# STM32N657 register map
File version: 1.0
CPU: CM55 r0p1, little endian, no MPU, FPU, vendor SysTick, 8 interrupt priority bits
Registers are 32-bit, read-write, reset 0x0 unless marked. A register's access mark holds for its fields unless they carry their own. Offsets are from the block's base; [hi:lo] are bit positions; {n}, {i} and the like mark numbered series.

## IWDG — Independent watchdog
Base 0x46004800
Same registers: IWDG_S 0x56004800
0x00 IWDG_KR wo — IWDG key register
  [15:0] KEY — Key value (write only, read 0x0000)
0x04 IWDG_PR — IWDG prescaler register
  [3:0] PR — Prescaler divider
    0=divider / 4; 1=divider / 8; 2=divider / 16; 3=divider / 32; 4=divider / 64; 5=divider / 128; 6=divider / 256; 7=divider / 512
0x08 IWDG_RLR reset 0xFFF — IWDG reload register
  [11:0] RL — Watchdog counter reload value
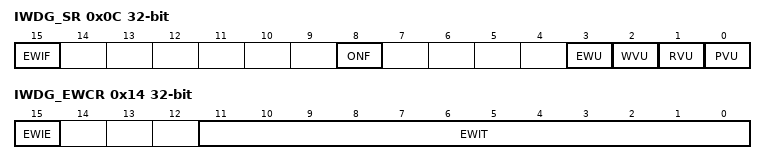
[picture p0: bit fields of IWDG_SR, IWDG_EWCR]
0x0C IWDG_SR ro — IWDG status register
  [15] EWIF — Watchdog early interrupt flag
  [8] ONF — Watchdog enable status bit
    0=The IWDG is not activated; 1=The IWDG is activated and needs to be refreshed regularly by the application
  [3] EWU — Watchdog interrupt comparator value update
  [2] WVU — Watchdog counter window value update
  [1] RVU — Watchdog counter reload value update
  [0] PVU — Watchdog prescaler value update
0x10 IWDG_WINR reset 0xFFF — IWDG window register
  [11:0] WIN — Watchdog counter window value
0x14 IWDG_EWCR — IWDG early wake-up interrupt register
  [15] EWIE — Watchdog early interrupt enable
    0=The early interrupt interface is disabled; 1=The early interrupt interface is enabled
  [11:0] EWIT — Watchdog counter window value
0x18 IWDG_ICR — IWDG interrupt clear register
  [15] EWIC — Watchdog early interrupt acknowledge

## MDIOS — Management data input/output
Base 0x40009400
Same registers: MDIOS_S 0x50009400
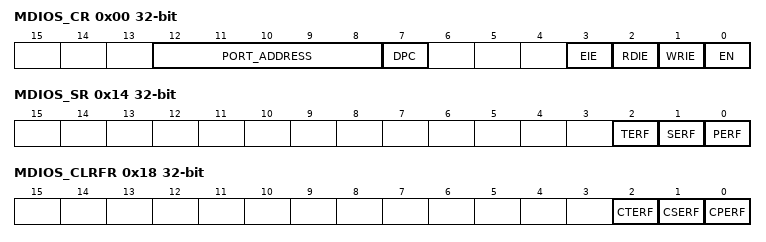
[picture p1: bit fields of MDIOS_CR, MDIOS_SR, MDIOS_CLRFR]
0x00 MDIOS_CR — MDIOS configuration register
  [12:8] PORT_ADDRESS — slave address
  [7] DPC — disable preamble check
    0=MDIO master must give preamble before each frame; 1=MDIO master can send each frame without a preceding preamble, and the MDIOS does not signal a preamble error
  [3] EIE — error interrupt enable
    0=Interrupt is disabled; 1=Interrupt is enabled
  [2] RDIE — register read interrupt enable
    0=Interrupt is disabled; 1=Interrupt is enabled
  [1] WRIE — register write interrupt enable
    0=Interrupt is disabled; 1=Interrupt is enabled
  [0] EN — peripheral enable
    0=MDIOS is disabled; 1=MDIOS is enabled and monitoring the MDIO bus (MDC/MDIO)
0x04 MDIOS_WRFR ro — MDIOS write flag register
  [31:0] WRF — write flags for MDIOS registers 0 to 31.
    0=MDIOS register x is not written by the MDIO master; 1=MDIOS register x is written by the MDIO master and the data is available in DIN[15:0] in the MDIOS_DINRx register
0x08 MDIOS_CWRFR — MDIOS clear write flag register
  [31:0] CWRF — clear the write flag
0x0C MDIOS_RDFR ro — MDIOS read flag register
  [31:0] RDF — read flags for MDIOS registers 0 to 31.
    0=MDIOS register x is not read by the MDIO master; 1=MDIOS register x is read by the MDIO master
0x10 MDIOS_CRDFR — MDIOS clear read flag register
  [31:0] CRDF — clear the read flag
0x14 MDIOS_SR ro — MDIOS status register
  [2] TERF — turnaround error flag
    0=No turnaround error has occurred; 1=A turnaround error has occurred
  [1] SERF — start error flag
    0=No start error has occurred; 1=A start error has occurred
  [0] PERF — preamble error flag
    0=No preamble error has occurred; 1=A preamble error has occurred
0x18 MDIOS_CLRFR — MDIOS clear flag register
  [2] CTERF — clear the turnaround error flag
  [1] CSERF — clear the start error flag
  [0] CPERF — clear the preamble error flag
{0x100+4i} MDIOS_DINR{i} ro (i=0..31) — MDIOS input data register {i}
  [15:0] DIN — input data received from MDIO master during write frames
{0x180+4i} MDIOS_DOUTR{i} (i=0..31) — MDIOS output data register {i}
  [15:0] DOUT — output data sent to MDIO Master during read frames

## PKA — Public key accelerator
Base 0x44022000
Same registers: PKA_S 0x54022000
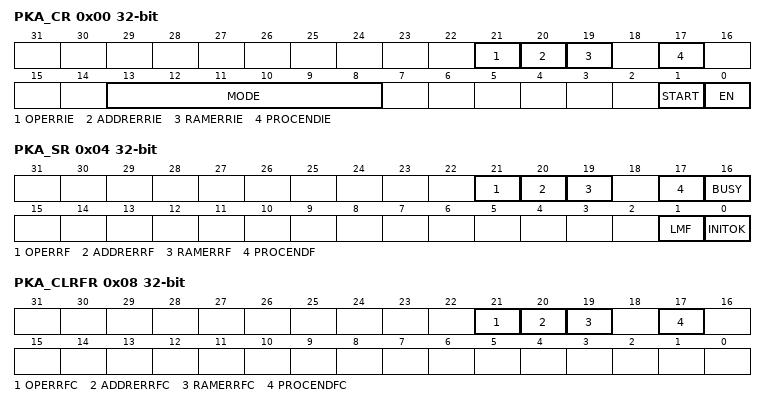
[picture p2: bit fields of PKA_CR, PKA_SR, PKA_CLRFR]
0x00 PKA_CR — PKA control register
  [21] OPERRIE — Operation error interrupt enable
    0=No interrupt is generated when OPERRF flag is set in PKA_SR; 1=An interrupt is generated when OPERRF flag is set in PKA_SR
  [20] ADDRERRIE — Address error interrupt enable
    0=No interrupt is generated when ADDRERRF flag is set in PKA_SR; 1=An interrupt is generated when ADDRERRF flag is set in PKA_SR
  [19] RAMERRIE — RAM error interrupt enable
    0=No interrupt is generated when RAMERRF flag is set in PKA_SR; 1=An interrupt is generated when RAMERRF flag is set in PKA_SR
  [17] PROCENDIE — End of operation interrupt enable
    0=No interrupt is generated when PROCENDF flag is set in PKA_SR; 1=An interrupt is generated when PROCENDF flag is set in PKA_SR
  [13:8] MODE — PKA operation code
    0=Montgomery parameter computation then modular exponentiation; 1=Montgomery parameter computation only; 2=Modular exponentiation only (Montgomery parameter must be loaded first); 3=Modular exponentiation (protected, used when manipulating secrets); 32=Montgomery parameter computation then ECC scalar multiplication; 36=ECDSA sign; 38=ECDSA verification; 40=Point on elliptic curve Fp check; 7=RSA CRT exponentiation; 8=Modular inversion; 9=Arithmetic addition; 10=Arithmetic subtraction; 11=Arithmetic multiplication; 12=Arithmetic comparison; 13=Modular reduction; 14=Modular addition; 15=Modular subtraction; 16=Montgomery multiplication; 35=ECC complete addition; 39=ECC double base ladder; 47=ECC projective to affine
  [1] START — start the operation
  [0] EN — PKA enable.
    0=Disable PKA; 1=Enable PKA.PKA becomes functional when INITOK is set by hardware in PKA_SR
0x04 PKA_SR ro — PKA status register
  [21] OPERRF — Operation error flag
    0=No event error; 1=An illegal or unknown operation has been selected in PKA_CR register
  [20] ADDRERRF — Address error flag
    0=No address error; 1=Address access is out of range (unmapped address)
  [19] RAMERRF — PKA RAM error flag
    0=No PKA RAM access error; 1=An AHB access to the PKA RAM occurred while the PKA core was computing and using its internal RAM (AHB PKA_RAM access are not allowed while PKA operation is in progress)
  [17] PROCENDF — PKA End of Operation flag
    0=Operation in progress; 1=PKA operation is completed. This flag is set when the BUSY bit is deasserted.
  [16] BUSY — PKA operation is in progress
    0=No operation is in progress (default); 1=An operation is in progress
  [1] LMF — Limited mode flag
    0=All values documented in MODE bitfield can be used; 1=Only ECDSA verification (MODE = 0x26) is supported by the PKA
  [0] INITOK — PKA initialization OK
    0=PKA is not initialized correctly. START bit cannot be set.; 1=PKA is initialized correctly and can be used normally
0x08 PKA_CLRFR wo — PKA clear flag register
  [21] OPERRFC — Clear operation error flag
    0=No action; 1=Clear the OPERRF flag in PKA_SR
  [20] ADDRERRFC — Clear address error flag
    0=No action; 1=Clear the ADDRERRF flag in PKA_SR
  [19] RAMERRFC — Clear PKA RAM error flag
    0=No action; 1=Clear the RAMERRF flag in PKA_SR
  [17] PROCENDFC — Clear PKA End of Operation flag
    0=No action; 1=Clear the PROCENDF flag in PKA_SR
